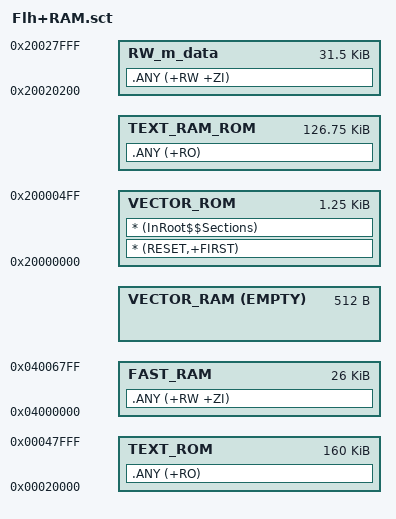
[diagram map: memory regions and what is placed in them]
#! armcc -E

#define STACK_SIZE 0x1800
#define RAM_ROM1_BASE	0x20000000
#define RAM_ROM1_SIZE	128*1024
; must use "VECTOR_RAM", "RW_m_data", "VECTOR_ROM" as names to work with "InstallIRQHandler()" API



LR_RAM_ROM1 RAM_ROM1_BASE RAM_ROM1_SIZE {
	  VECTOR_ROM +0 0x500 { ; vector table
		* (RESET,+FIRST)
		* (InRoot$$Sections)
	  }

	  TEXT_RAM_ROM +0 RAM_ROM1_SIZE-0x500  {
	  	.ANY (+RO)
	  }
	  
}

LR_IROM2 0x00020000 384*1024 {

	  TEXT_ROM +0 160*1024 { ; limit this ER size to force linker to put some RO to "TEXT_RAM_ROM"
		.ANY (+RO)
	  }

  ; >>> RAMX regions
	  ; RAM vector table, unless "InstallIRQHandler()" is called, not used
	  FAST_RAM 0x04000000 32*1024 - STACK_SIZE {
		 .ANY (+RW +ZI)
	  }	
  ; <<<
  
  ; >>> AHB RAM (2 cycles access) regions, main R/W
	  VECTOR_RAM +0 EMPTY 0x200 { ; RAM vector region (in RAMX)
	  }
	  RW_m_data 0x20020200 32*1024-0x200 { ; RW data
		.ANY (+RW +ZI)
	  }
  ; <<<
  
  ; >>> SDRAM >>>
	  ;RW_FB 0xA0000000 EMPTY UNINIT 1024*1024  {
	  ;}
	  
	  ;RW_SDRAM 0xA0100000 EMPTY UNINIT (32-1)*1024*1024  {
	  ;}
; <<<
}
